# RE01_1500KB register map
Vendor: Renesas Electronics Corporation; Series: RE01_1500KB; File version: 1.20
CPU: CM0PLUS r0p1, little endian, MPU, no FPU, VTOR, 2 interrupt priority bits
Registers are 8-bit, read-write, reset 0x0 unless marked. A register's access mark holds for its fields unless they carry their own. Offsets are from the block's base; [hi:lo] are bit positions; {n}, {i} and the like mark numbered series; 'fields as' and 'values as' point back to an identical list.

## DOC — Data Operation Circuit
Base 0x40054100
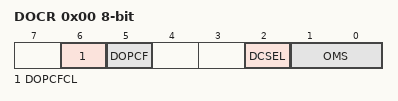
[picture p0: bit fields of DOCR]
0x00 DOCR — DOC Control Register
  [6] DOPCFCL — DOPCF Clear
    0=Maintains the DOPCF flag state; 1=Clears the DOPCF flag
  [5] DOPCF ro — Data Operation Circuit FlagIndicates the result of an operation.
  [2] DCSEL — Detection Condition Select
    0=DOPCF is set when data mismatch is detected; 1=DOPCF is set when data match is detected
  [1:0] OMS — Operating Mode Select
    0=Data comparison mode; 1=Data addition mode; 2=Data subtraction mode; 3=Setting prohibited
0x02 DODIR 16-bit — DOC Data Input Register
  [15:0] DODIR — 16-bit read-write register in which 16-bit data for use in the operations are stored.
0x04 DODSR 16-bit — DOC Data Setting Register
  [15:0] DODSR — This register stores 16-bit data for use as a reference in data comparison mode. This register also stores the results of operations in data addition and data subtraction modes.

## DTC — Data Transfer Controller
Base 0x40005400
0x00 DTCCR reset 0x8
  [4] RRS
0x04 DTCVBR 32-bit — DTC Vector Base Register
  [31:0] DTCVBR — DTC Vector Base Address
0x0C DTCST — DTC Module Start Register
  [0] DTCST — DTC Module Start
    0=DTC module stop; 1=DTC module start
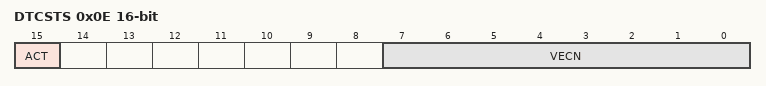
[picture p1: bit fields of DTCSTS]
0x0E DTCSTS 16-bit — DTC Status Register
  [15] ACT ro — DTC Active Flag
    0=DTC transfer operation is not in progress; 1=DTC transfer operation is in progress
  [7:0] VECN ro — DTC-Activating Vector Number Monitoring

## EHC — Energy Harvest Control Circuit
Base 0x01008140
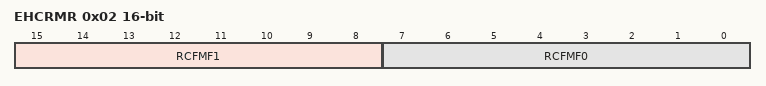
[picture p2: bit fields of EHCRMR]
0x02 EHCRMR 16-bit ro reset not defined — EHC Registance value monitor register
  [15:8] RCFMF1, [7:0] RCFMF0

## ELC — Event Link Controller
Base 0x40041000
0x00 ELCR — Event Link Controller Register
  [7] ELCON — All Event Link Enable
    0=ELC function is disabled; 1=ELC function is enabled
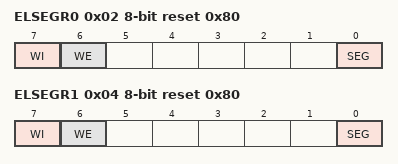
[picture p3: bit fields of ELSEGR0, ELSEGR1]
0x02 ELSEGR0 reset 0x80
  [7] WI wo, [6] WE, [0] SEG wo
0x04 ELSEGR1 reset 0x80
  [7] WI wo, [6] WE, [0] SEG wo
{0x10+4i} ELSR{i} (i=0..3) 16-bit — Event Link Setting Register {i}
  [7:0] ELS — Event Link Select
    0=Event output to the corresponding peripheral module is disabled; other=others (Set the number for the event signal to be linked.)
0x30 ELSR{x} (x=8,12; step 0x10) 16-bit — Event Link Setting Register {x}
  fields as ELSR0
{0x10+4i} ELSR{i} (i=14..15) 16-bit — Event Link Setting Register {i}
  fields as ELSR0
{0x10+4i} ELSR{i} (i=18..19) 16-bit — Event Link Setting Register {i}
  fields as ELSR0

## GDT
Base 0x40070800
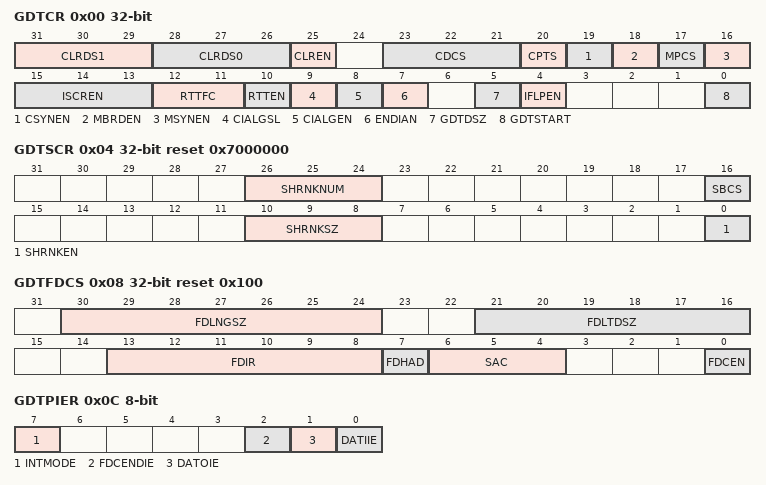
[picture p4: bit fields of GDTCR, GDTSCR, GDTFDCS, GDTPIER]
0x00 GDTCR 32-bit
  [31:29] CLRDS1
  [28:26] CLRDS0
  [25] CLREN
  [23:21] CDCS
  [20] CPTS
  [19] CSYNEN
  [18] MBRDEN
  [17] MPCS
  [16] MSYNEN
  [15:13] ISCREN
    0=000; 1=001; 2=010; 3=011; 4=100; 5=101; 6=110; 7=111
  [12:11] RTTFC
    0=00; 1=01; 2=10; 3=11
  [10] RTTEN
  [9] CIALGSL
  [8] CIALGEN
  [7] ENDIAN
  [5] GDTDSZ
  [4] IFLPEN
  [0] GDTSTART
0x04 GDTSCR 32-bit reset 0x7000000
  [26:24] SHRNKNUM
    0=000; 1=001; 2=010; 3=011; 4=100; 5=101; 6=110; 7=111
  [16] SBCS
  [10:8] SHRNKSZ
    0=000; 1=001; 2=010; 3=011; 4=100; 5=101; 6=110; 7=111
  [0] SHRNKEN
0x08 GDTFDCS 32-bit reset 0x100
  [30:24] FDLNGSZ
  [21:16] FDLTDSZ
  [13:8] FDIR
  [7] FDHAD
  [6:4] SAC
    0=000; 1=001; 2=010; 3=011; 4=100; 5=101; 6=110; 7=111
  [0] FDCEN
0x0C GDTPIER
  [7] INTMODE, [2] FDCENDIE, [1] DATOIE, [0] DATIIE
{0x100+4i} GDTIBUF{i} (i=0..47) 32-bit
  [31:0] GDTIBUF
{0x200+4i} GDTOBUF{i} (i=0..31) 32-bit
  [31:0] GDTOBUF

## GPT_OPS — Output Phase Switching Controller
Base 0x40055FF0
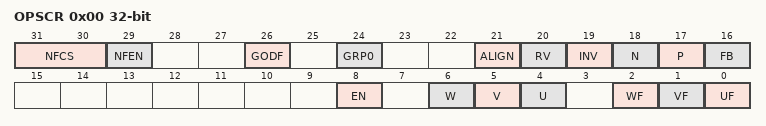
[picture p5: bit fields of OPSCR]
0x00 OPSCR 32-bit — Output Phase Switching Control Register
  [31:30] NFCS — External Input Noise Filter Clock selectionNoise filter sampling clock setting of the external input.
    0=PCLKD/1; 1=PCLKD/4; 2=PCLKD/16; 3=PCLKD/64
  [29] NFEN — External Input Noise Filter Enable
    0=Do not use a noise filter to the external input; 1=Use a noise filter to the external input
  [26] GODF — Group output disable function
    0=This bit function is ignored; 1=Group output is disable
  [24] GRP0 — Output disabled source selection
    0=Select Group A output disable source; 1=Select Group B output disable source
  [21] ALIGN ro — Input phase alignment
    0=Input phase is aligned to PCLKB; 1=Input phase is aligned PWM
  [20] RV — Output phase rotation direction reversal
    0=U/V/W-Phase output; 1=Output to reverse the V / W-phase
  [19] INV — Invert-Phase Output Control
    0=Positive Logic (Active High)output; 1=Negative Logic (Active Low)output
  [18] N — Negative-Phase Output (N) Control
    0=Level signal output; 1=PWM signal output (PWM of GPT162)
  [17] P — Positive-Phase Output (P) Control
    0=Level signal output; 1=PWM signal output (PWM of GPT162)
  [16] FB — External Feedback Signal EnableThis bit selects the input phase from the software settings and external input.
    0=Select the external input; 1=Select the soft setting(OPSCR.UF, VF, WF)
  [8] EN — Enable-Phase Output Control
    0=Not Output(Hi-Z external terminals); 1=Output
  [6] W ro — Input W-Phase MonitorThis bit monitors the state of the input phase.OPSCR.FB=0:External input monitoring by PCLKDOPSCR.FB=1:Software settings (UF/VF/WF)
  [5] V ro — Input V-Phase MonitorThis bit monitors the state of the input phase.OPSCR.FB=0:External input monitoring by PCLKDOPSCR.FB=1:Software settings (UF/VF/WF)
  [4] U ro — Input U-Phase MonitorThis bit monitors the state of the input phase.OPSCR.FB=0:External input monitoring by PCLKDOPSCR.FB=1:Software settings (UF/VF/WF)
  [2] WF — Input Phase Soft Setting UFThis bit sets the input phase by the software settings.This bit setting is valid when the OPSCR.FB bit = 1.
  [1] VF — Input Phase Soft Setting VFThis bit sets the input phase by the software settings.This bit setting is valid when the OPSCR.FB bit = 1.
  [0] UF — Input Phase Soft Setting WFThis bit sets the input phase by the software settings.This bit setting is valid when the OPSCR.FB bit = 1.
